# HT32F52342_52 register map
File version: 1.0
CPU: CM0+ r0p1, little endian, no MPU, no FPU, 4 interrupt priority bits
Registers are 32-bit, read-write, reset 0x0 unless marked. A register's access mark holds for its fields unless they carry their own. Offsets are from the block's base; [hi:lo] are bit positions; {n}, {i} and the like mark numbered series; 'fields as' and 'values as' point back to an identical list.

## AFIO
Base 0x40022000
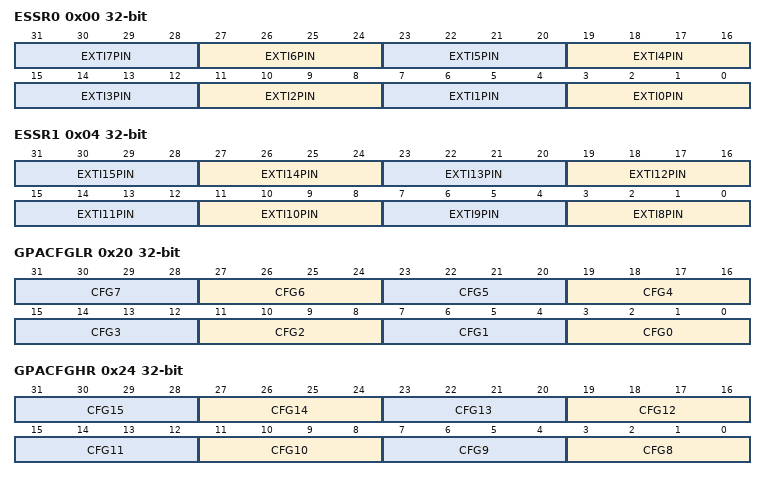
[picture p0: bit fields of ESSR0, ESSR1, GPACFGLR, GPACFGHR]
0x00 ESSR0
  [4n+3:4n] EXTI{n}PIN (n=0..7)
0x04 ESSR1
  [4n-29:4n-32] EXTI{n}PIN (n=8..15)
0x20 GPACFGLR
  [4n+3:4n] CFG{n} (n=0..7)
0x24 GPACFGHR
  [4n-29:4n-32] CFG{n} (n=8..15)
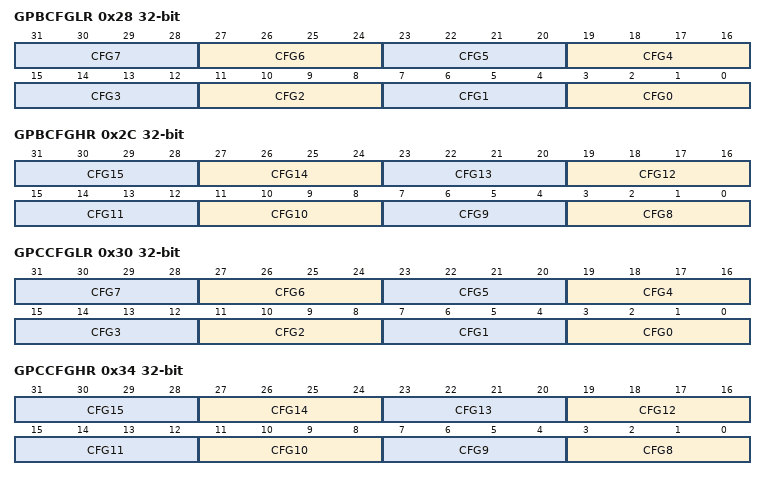
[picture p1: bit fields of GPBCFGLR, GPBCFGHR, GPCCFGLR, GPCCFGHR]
0x28 GPBCFGLR
  [4n+3:4n] CFG{n} (n=0..7)
0x2C GPBCFGHR
  [4n-29:4n-32] CFG{n} (n=8..15)
0x30 GPCCFGLR
  [4n+3:4n] CFG{n} (n=0..7)
0x34 GPCCFGHR
  [4n-29:4n-32] CFG{n} (n=8..15)
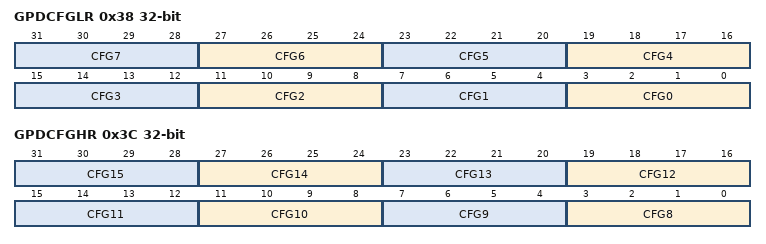
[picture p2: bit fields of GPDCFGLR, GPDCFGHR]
0x38 GPDCFGLR
  [4n+3:4n] CFG{n} (n=0..7)
0x3C GPDCFGHR
  [4n-29:4n-32] CFG{n} (n=8..15)

## EXTI
Base 0x40024000
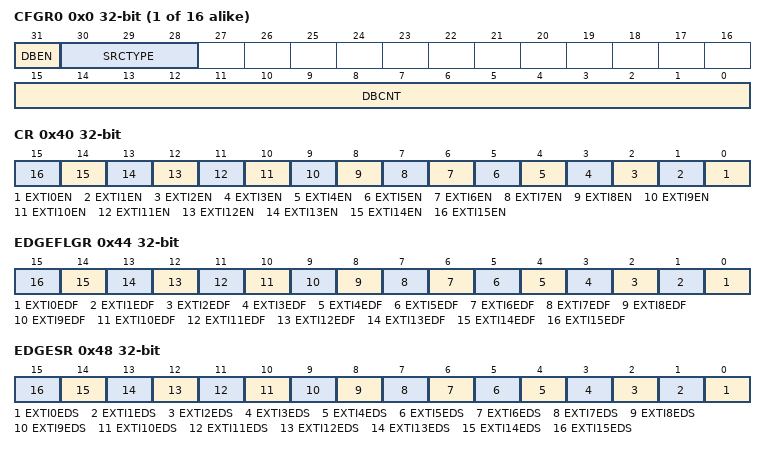
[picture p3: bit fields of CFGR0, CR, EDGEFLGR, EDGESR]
{0x0+4i} CFGR{i} (i=0..15)
  [31] DBEN, [30:28] SRCTYPE, [15:0] DBCNT
0x40 CR
  [n] EXTI{n}EN (n=0..15)
0x44 EDGEFLGR
  [n] EXTI{n}EDF (n=0..15)
0x48 EDGESR
  [n] EXTI{n}EDS (n=0..15)
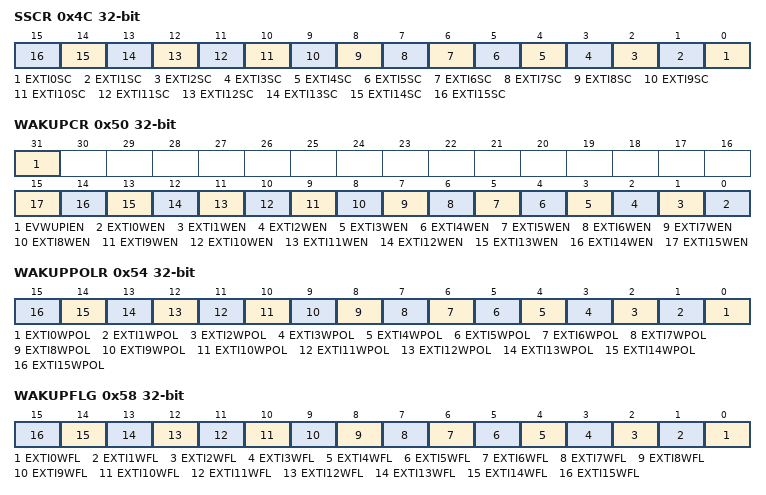
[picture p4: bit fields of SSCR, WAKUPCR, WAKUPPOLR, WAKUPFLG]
0x4C SSCR
  [n] EXTI{n}SC (n=0..15)
0x50 WAKUPCR
  [31] EVWUPIEN, [n] EXTI{n}WEN (n=0..15)
0x54 WAKUPPOLR
  [n] EXTI{n}WPOL (n=0..15)
0x58 WAKUPFLG
  [n] EXTI{n}WFL (n=0..15)

## ADC
Base 0x40010000
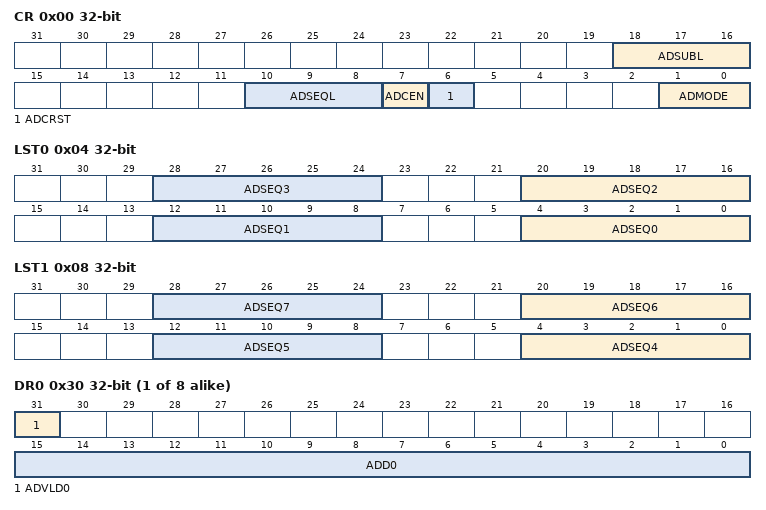
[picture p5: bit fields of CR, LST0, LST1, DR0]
0x00 CR
  [18:16] ADSUBL, [10:8] ADSEQL, [7] ADCEN, [6] ADCRST, [1:0] ADMODE
0x04 LST0
  [8n+4:8n] ADSEQ{n} (n=0..3)
0x08 LST1
  [8n-28:8n-32] ADSEQ{n} (n=4..7)
0x20 STR
  [7:0] ADST
{0x30+4i} DR{i} (i=0..7)
  [31] ADVLD{i}, [15:0] ADD{i}
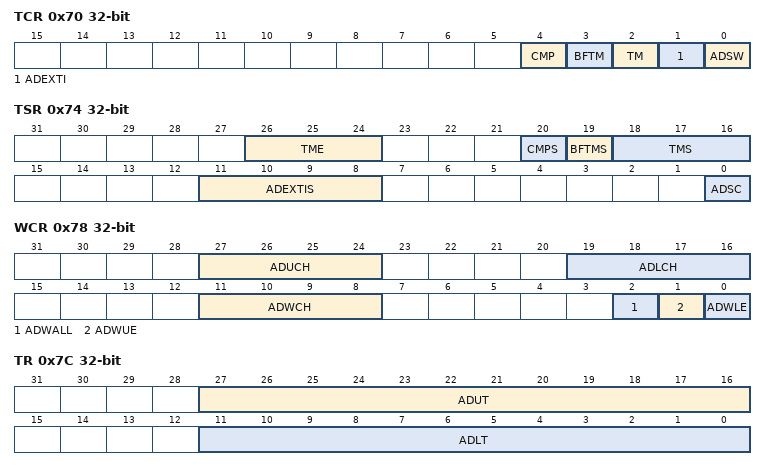
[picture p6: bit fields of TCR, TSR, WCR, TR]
0x70 TCR
  [4] CMP, [3] BFTM, [2] TM, [1] ADEXTI, [0] ADSW
0x74 TSR
  [26:24] TME, [20] CMPS, [19] BFTMS, [18:16] TMS, [11:8] ADEXTIS, [0] ADSC
0x78 WCR
  [27:24] ADUCH, [19:16] ADLCH, [11:8] ADWCH, [2] ADWALL, [1] ADWUE, [0] ADWLE
0x7C TR
  [27:16] ADUT, [11:0] ADLT
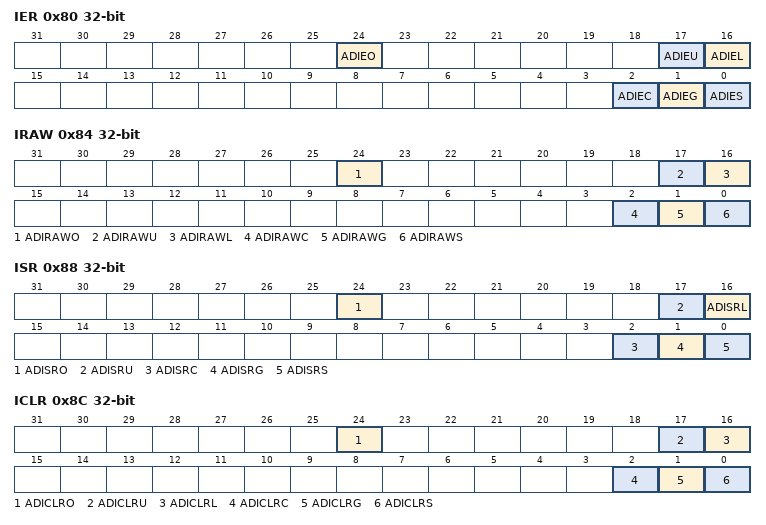
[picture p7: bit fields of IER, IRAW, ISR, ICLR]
0x80 IER — IMR
  [24] ADIEO, [17] ADIEU, [16] ADIEL, [2] ADIEC, [1] ADIEG, [0] ADIES
0x84 IRAW
  [24] ADIRAWO, [17] ADIRAWU, [16] ADIRAWL, [2] ADIRAWC, [1] ADIRAWG, [0] ADIRAWS
0x88 ISR
  [24] ADISRO, [17] ADISRU, [16] ADISRL, [2] ADISRC, [1] ADISRG, [0] ADISRS
0x8C ICLR
  [24] ADICLRO, [17] ADICLRU, [16] ADICLRL, [2] ADICLRC, [1] ADICLRG, [0] ADICLRS
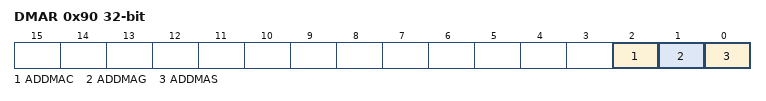
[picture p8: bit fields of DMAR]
0x90 DMAR
  [2] ADDMAC, [1] ADDMAG, [0] ADDMAS

## CMP
Base 0x40058000
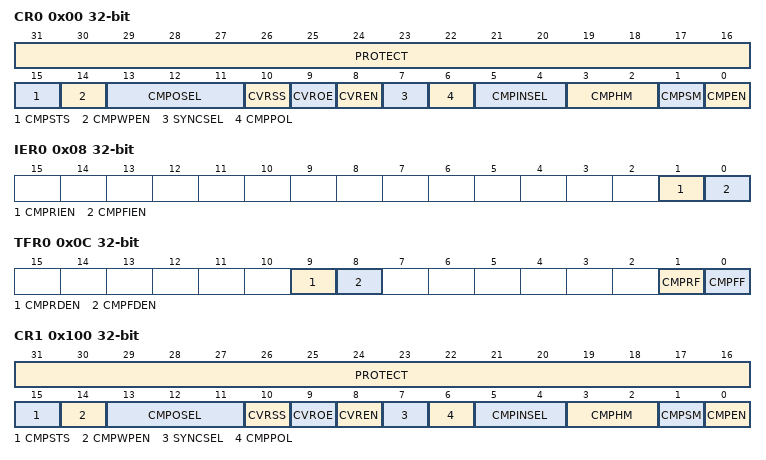
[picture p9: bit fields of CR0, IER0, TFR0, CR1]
0x00 CR0
  [31:16] PROTECT, [15] CMPSTS, [14] CMPWPEN, [13:11] CMPOSEL, [10] CVRSS, [9] CVROE, [8] CVREN, [7] SYNCSEL, [6] CMPPOL, [5:4] CMPINSEL, [3:2] CMPHM, [1] CMPSM, [0] CMPEN
0x04 VALR0
  [5:0] CVRVAL
0x08 IER0
  [1] CMPRIEN, [0] CMPFIEN
0x0C TFR0
  [9] CMPRDEN, [8] CMPFDEN, [1] CMPRF, [0] CMPFF
0x100 CR1
  fields as CR0
0x104 VALR1
  [5:0] CVRVAL
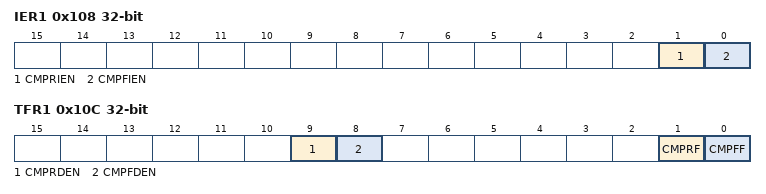
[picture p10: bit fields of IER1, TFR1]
0x108 IER1
  [1] CMPRIEN, [0] CMPFIEN
0x10C TFR1
  [9] CMPRDEN — CMPRF
  [8] CMPFDEN
  [1] CMPRF
  [0] CMPFF

## MCTM0
Base 0x4002C000
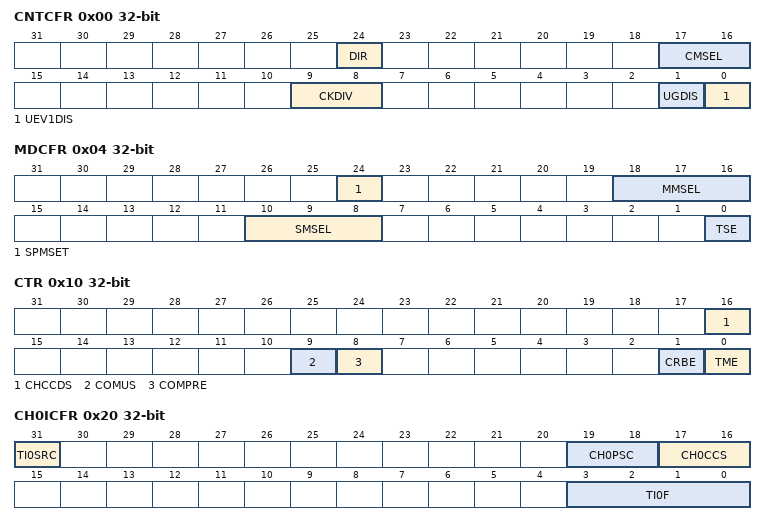
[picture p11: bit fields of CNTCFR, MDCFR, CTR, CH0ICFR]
0x00 CNTCFR
  [24] DIR, [17:16] CMSEL, [9:8] CKDIV, [1] UGDIS, [0] UEV1DIS
0x04 MDCFR
  [24] SPMSET, [18:16] MMSEL, [10:8] SMSEL, [0] TSE
0x08 TRCFR
  [3:0] TRSEL
0x10 CTR
  [16] CHCCDS, [9] COMUS, [8] COMPRE, [1] CRBE, [0] TME
0x20 CH0ICFR
  [31] TI0SRC, [19:18] CH0PSC, [17:16] CH0CCS, [3:0] TI0F
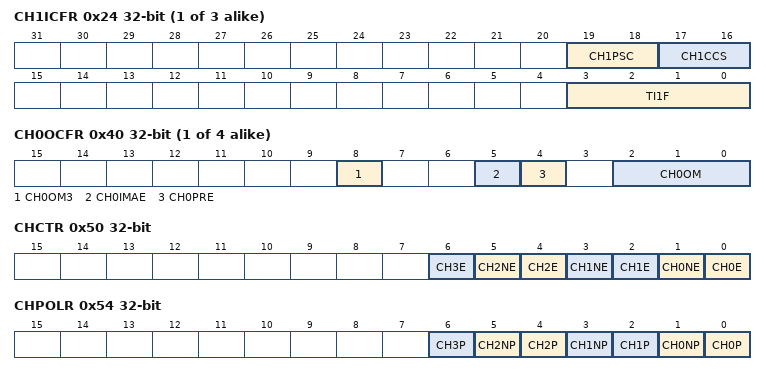
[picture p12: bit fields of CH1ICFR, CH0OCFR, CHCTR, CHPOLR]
{0x20+4i} CH{i}ICFR (i=1..3)
  [19:18] CH{i}PSC, [17:16] CH{i}CCS, [3:0] TI{i}F
{0x40+4i} CH{i}OCFR (i=0..3)
  [8] CH{i}OM3, [5] CH{i}IMAE, [4] CH{i}PRE, [2:0] CH{i}OM
0x50 CHCTR
  [2n] CH{n}E (n=0..3), [5] CH2NE, [3] CH1NE, [1] CH0NE
0x54 CHPOLR
  [2n] CH{n}P (n=0..3), [5] CH2NP, [3] CH1NP, [1] CH0NP
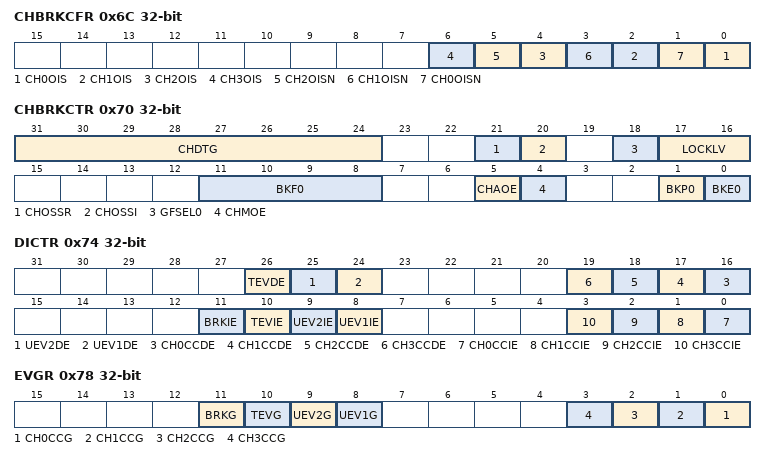
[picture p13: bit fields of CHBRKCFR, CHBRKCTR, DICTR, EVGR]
0x6C CHBRKCFR
  [2n] CH{n}OIS (n=0..3), [5] CH2OISN, [3] CH1OISN, [1] CH0OISN
0x70 CHBRKCTR
  [31:24] CHDTG, [21] CHOSSR, [20] CHOSSI, [18] GFSEL0, [17:16] LOCKLV, [11:8] BKF0, [5] CHAOE, [4] CHMOE, [1] BKP0, [0] BKE0
0x74 DICTR
  [26] TEVDE, [25] UEV2DE, [24] UEV1DE, [n+16] CH{n}CCDE (n=0..3), [11] BRKIE, [10] TEVIE, [9] UEV2IE, [8] UEV1IE, [n] CH{n}CCIE (n=0..3)
0x78 EVGR
  [11] BRKG, [10] TEVG, [9] UEV2G, [8] UEV1G, [n] CH{n}CCG (n=0..3)
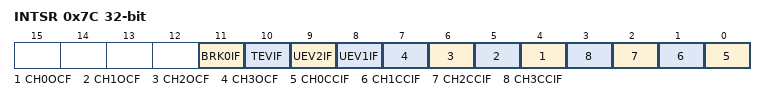
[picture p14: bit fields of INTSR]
0x7C INTSR
  [11] BRK0IF, [10] TEVIF, [9] UEV2IF, [8] UEV1IF, [n+4] CH{n}OCF (n=0..3), [n] CH{n}CCIF (n=0..3)
0x80 CNTR
  [15:0] CNTV
0x84 PSCR
  [15:0] PSCV
0x88 CRR
  [15:0] CRV
0x8C REPR
  [7:0] REPV
{0x90+4i} CH{i}CCR (i=0..3)
  [15:0] CH{i}CCV
{0xA0+4i} CH{i}ACR (i=0..3)
  [15:0] CH{i}ACV

## Notices in the file
Copyright (C) 2010 ARM Limited. All rights reserved.
ARM Limited (ARM) is supplying this SVD description for use with Cortex-M3
processor based microcontrollers.  This file and or content can be freely
distributed within development tools that are supporting such ARM based
processors.
THIS SOFTWARE IS PROVIDED "AS IS".  NO WARRANTIES, WHETHER EXPRESS, IMPLIED
OR STATUTORY, INCLUDING, BUT NOT LIMITED TO, IMPLIED WARRANTIES OF
MERCHANTABILITY AND FITNESS FOR A PARTICULAR PURPOSE APPLY TO THIS SOFTWARE.
ARM SHALL NOT, IN ANY CIRCUMSTANCES, BE LIABLE FOR SPECIAL, INCIDENTAL, OR
CONSEQUENTIAL DAMAGES, FOR ANY REASON WHATSOEVER.
